AUTOSAR XML (schema 4-0-3)
standard types defined: Boolean, UInt16, UInt32, UInt8
package /AUTOSAR_Platform/DataConstrs
  range DC_Boolean: raw 0..1
  range DC_UInt16: raw 0..65535
  range DC_UInt8: raw 0..255
package /PATAC/MSM/ComponentTypes
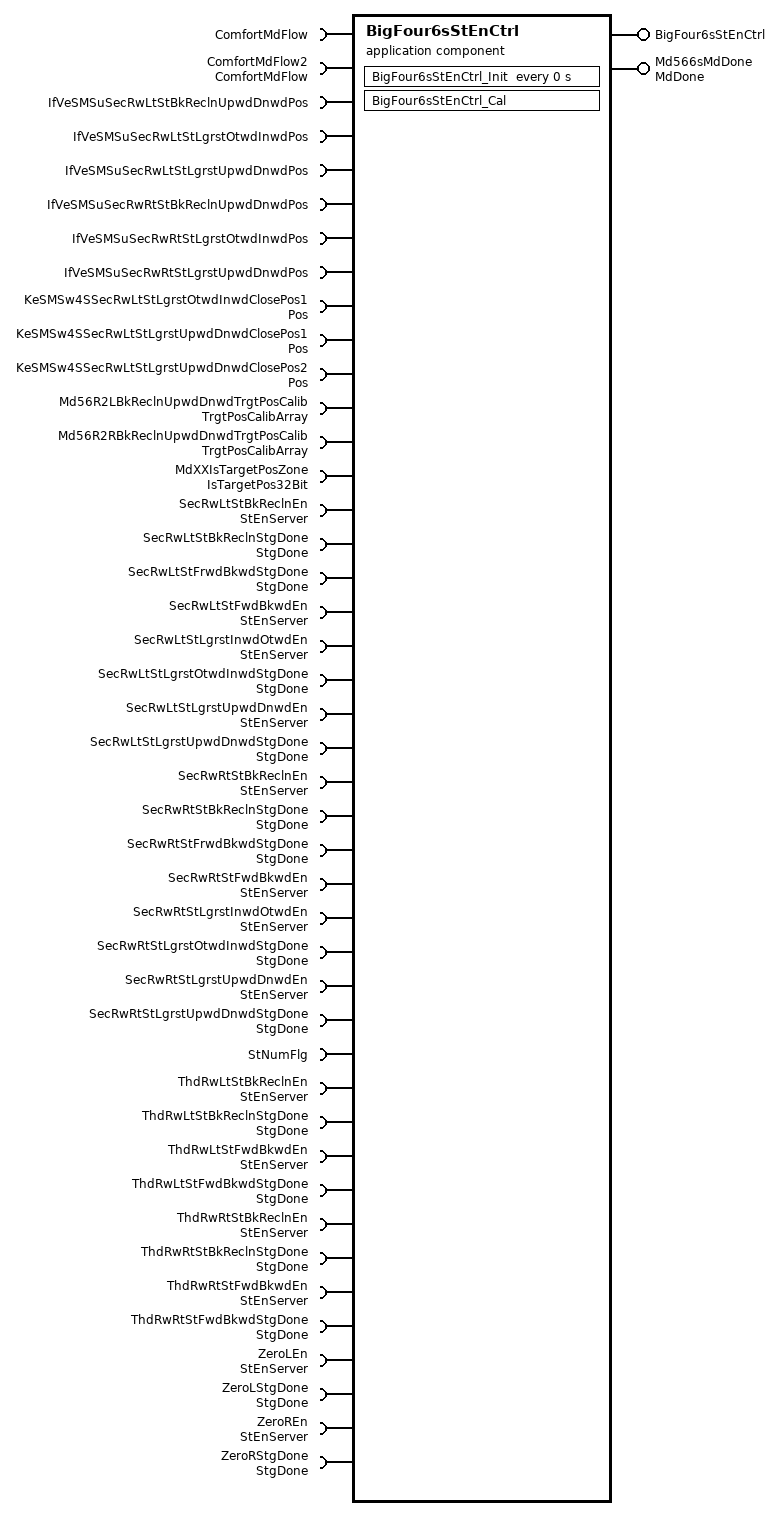
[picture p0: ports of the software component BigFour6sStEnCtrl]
  application sw component type BigFour6sStEnCtrl
    provide port BigFour6sStEnCtrl: server-com-spec{operation=BigFour6sStEnCtrl/Cal, queue-length=1}, provided-interface=BigFour6sStEnCtrl
    provide port Md566sMdDone: nonqueued-sender-com-spec{data-element=MdDone/Val, init-value=0}, provided-interface=MdDone
    43 x require port:
      ComfortMdFlow: client-com-spec=ComfortMdFlow/Cal, required-interface=ComfortMdFlow
      ComfortMdFlow2: client-com-spec=ComfortMdFlow/Cal, required-interface=ComfortMdFlow
      IfVeSMSuSecRwLtStBkReclnUpwdDnwdPos: nonqueued-receiver-com-spec{data-element=IfVeSMSuSecRwLtStBkReclnUpwdDnwdPos/Val, filter=data-filter-type=ALWAYS, init-value=0}, required-interface=IfVeSMSuSecRwLtStBkReclnUpwdDnwdPos
      IfVeSMSuSecRwLtStLgrstOtwdInwdPos: nonqueued-receiver-com-spec{data-element=IfVeSMSuSecRwLtStLgrstOtwdInwdPos/Val, filter=data-filter-type=ALWAYS, init-value=0}, required-interface=IfVeSMSuSecRwLtStLgrstOtwdInwdPos
      IfVeSMSuSecRwLtStLgrstUpwdDnwdPos: nonqueued-receiver-com-spec{data-element=IfVeSMSuSecRwLtStLgrstUpwdDnwdPos/Val, filter=data-filter-type=ALWAYS, init-value=0}, required-interface=IfVeSMSuSecRwLtStLgrstUpwdDnwdPos
      IfVeSMSuSecRwRtStBkReclnUpwdDnwdPos: nonqueued-receiver-com-spec{data-element=IfVeSMSuSecRwRtStBkReclnUpwdDnwdPos/Val, filter=data-filter-type=ALWAYS, init-value=0}, required-interface=IfVeSMSuSecRwRtStBkReclnUpwdDnwdPos
      IfVeSMSuSecRwRtStLgrstOtwdInwdPos: nonqueued-receiver-com-spec{data-element=IfVeSMSuSecRwRtStLgrstOtwdInwdPos/Val, filter=data-filter-type=ALWAYS, init-value=0}, required-interface=IfVeSMSuSecRwRtStLgrstOtwdInwdPos
      IfVeSMSuSecRwRtStLgrstUpwdDnwdPos: nonqueued-receiver-com-spec{data-element=IfVeSMSuSecRwRtStLgrstUpwdDnwdPos/Val, filter=data-filter-type=ALWAYS, init-value=0}, required-interface=IfVeSMSuSecRwRtStLgrstUpwdDnwdPos
      KeSMSw4SSecRwLtStLgrstOtwdInwdClosePos1: parameter-require-com-spec{init-value=0, parameter=Val}, required-interface=Pos
      KeSMSw4SSecRwLtStLgrstUpwdDnwdClosePos1: parameter-require-com-spec{init-value=0, parameter=Val}, required-interface=Pos
      KeSMSw4SSecRwLtStLgrstUpwdDnwdClosePos2: parameter-require-com-spec{init-value=0, parameter=Val}, required-interface=Pos
      Md56R2LBkReclnUpwdDnwdTrgtPosCalib: nonqueued-receiver-com-spec{data-element=TrgtPosArray, filter=data-filter-type=ALWAYS, init-value=[4095, 4095, 4095]}, required-interface=TrgtPosCalibArray
      Md56R2RBkReclnUpwdDnwdTrgtPosCalib: nonqueued-receiver-com-spec{data-element=TrgtPosArray, filter=data-filter-type=ALWAYS, init-value=[4095, 4095, 4095]}, required-interface=TrgtPosCalibArray
      MdXXIsTargetPosZone: nonqueued-receiver-com-spec{data-element=IsTargetPos32Bit/Val, filter=data-filter-type=ALWAYS, init-value=0}, required-interface=IsTargetPos32Bit
      SecRwLtStBkReclnEn: required-com-specs=[Clear, Get, Set], required-interface=StEnServer
      SecRwLtStBkReclnStgDone: nonqueued-receiver-com-spec{data-element=StgDone/Val, filter=data-filter-type=ALWAYS, init-value=0}, required-interface=StgDone
      SecRwLtStFrwdBkwdStgDone: nonqueued-receiver-com-spec{data-element=StgDone/Val, filter=data-filter-type=ALWAYS, init-value=0}, required-interface=StgDone
      SecRwLtStFwdBkwdEn: required-com-specs=[Clear, Get, Set], required-interface=StEnServer
      SecRwLtStLgrstInwdOtwdEn: required-com-specs=[Clear, Get, Set], required-interface=StEnServer
      SecRwLtStLgrstOtwdInwdStgDone: nonqueued-receiver-com-spec{data-element=StgDone/Val, filter=data-filter-type=ALWAYS, init-value=0}, required-interface=StgDone
      SecRwLtStLgrstUpwdDnwdEn: required-com-specs=[Clear, Get, Set], required-interface=StEnServer
      SecRwLtStLgrstUpwdDnwdStgDone: nonqueued-receiver-com-spec{data-element=StgDone/Val, filter=data-filter-type=ALWAYS, init-value=0}, required-interface=StgDone
      SecRwRtStBkReclnEn: required-com-specs=[Clear, Get, Set], required-interface=StEnServer
      SecRwRtStBkReclnStgDone: nonqueued-receiver-com-spec{data-element=StgDone/Val, filter=data-filter-type=ALWAYS, init-value=0}, required-interface=StgDone
      SecRwRtStFrwdBkwdStgDone: nonqueued-receiver-com-spec{data-element=StgDone/Val, filter=data-filter-type=ALWAYS, init-value=0}, required-interface=StgDone
      SecRwRtStFwdBkwdEn: required-com-specs=[Clear, Get, Set], required-interface=StEnServer
      SecRwRtStLgrstInwdOtwdEn: required-com-specs=[Clear, Get, Set], required-interface=StEnServer
      SecRwRtStLgrstOtwdInwdStgDone: nonqueued-receiver-com-spec{data-element=StgDone/Val, filter=data-filter-type=ALWAYS, init-value=0}, required-interface=StgDone
      SecRwRtStLgrstUpwdDnwdEn: required-com-specs=[Clear, Get, Set], required-interface=StEnServer
      SecRwRtStLgrstUpwdDnwdStgDone: nonqueued-receiver-com-spec{data-element=StgDone/Val, filter=data-filter-type=ALWAYS, init-value=0}, required-interface=StgDone
      StNumFlg: required-interface=StNumFlg
        required-com-specs:
          data-element=Is4s, filter=data-filter-type=ALWAYS, init-value=0
          data-element=Is6s, filter=data-filter-type=ALWAYS, init-value=0
          data-element=Is6s7s, filter=data-filter-type=ALWAYS, init-value=0
          data-element=Is7s, filter=data-filter-type=ALWAYS, init-value=0
      ThdRwLtStBkReclnEn: required-com-specs=[Clear, Get, Set], required-interface=StEnServer
      ThdRwLtStBkReclnStgDone: nonqueued-receiver-com-spec{data-element=StgDone/Val, filter=data-filter-type=ALWAYS, init-value=0}, required-interface=StgDone
      ThdRwLtStFwdBkwdEn: required-com-specs=[Clear, Get, Set], required-interface=StEnServer
      ThdRwLtStFwdBkwdStgDone: nonqueued-receiver-com-spec{data-element=StgDone/Val, filter=data-filter-type=ALWAYS, init-value=0}, required-interface=StgDone
      ThdRwRtStBkReclnEn: required-com-specs=[Clear, Get, Set], required-interface=StEnServer
      ThdRwRtStBkReclnStgDone: nonqueued-receiver-com-spec{data-element=StgDone/Val, filter=data-filter-type=ALWAYS, init-value=0}, required-interface=StgDone
      ThdRwRtStFwdBkwdEn: required-com-specs=[Clear, Get, Set], required-interface=StEnServer
      ThdRwRtStFwdBkwdStgDone: nonqueued-receiver-com-spec{data-element=StgDone/Val, filter=data-filter-type=ALWAYS, init-value=0}, required-interface=StgDone
      ZeroLEn: required-com-specs=[Clear, Get, Set], required-interface=StEnServer
      ZeroLStgDone: nonqueued-receiver-com-spec{data-element=StgDone/Val, filter=data-filter-type=ALWAYS, init-value=0}, required-interface=StgDone
      ZeroREn: required-com-specs=[Clear, Get, Set], required-interface=StEnServer
      ZeroRStgDone: nonqueued-receiver-com-spec{data-element=StgDone/Val, filter=data-filter-type=ALWAYS, init-value=0}, required-interface=StgDone
    behavior BigFour6sStEnCtrl_InternalBehavior
      operation invoked event OIT_BigFour6sStEnCtrl_Cal_BigFour6sStEnCtrl_Cal: start-on-event=BigFour6sStEnCtrl_Cal, operation=BigFour6sStEnCtrl.Cal
      timing event BigFour6sStEnCtrl_InitEvent: start-on-event=BigFour6sStEnCtrl_Init, period=0
      runnable BigFour6sStEnCtrl_Cal
        data-receive-point-by-arguments:
          27 x access:
            REC_IfVeSMSuSecRwLtStBkReclnUpwdDnwdPos_Val: accessed-variable=IfVeSMSuSecRwLtStBkReclnUpwdDnwdPos.Val
            REC_IfVeSMSuSecRwLtStLgrstOtwdInwdPos_Val: accessed-variable=IfVeSMSuSecRwLtStLgrstOtwdInwdPos.Val
            REC_IfVeSMSuSecRwLtStLgrstUpwdDnwdPos_Val: accessed-variable=IfVeSMSuSecRwLtStLgrstUpwdDnwdPos.Val
            REC_IfVeSMSuSecRwRtStBkReclnUpwdDnwdPos_Val: accessed-variable=IfVeSMSuSecRwRtStBkReclnUpwdDnwdPos.Val
            REC_IfVeSMSuSecRwRtStLgrstOtwdInwdPos_Val: accessed-variable=IfVeSMSuSecRwRtStLgrstOtwdInwdPos.Val
            REC_IfVeSMSuSecRwRtStLgrstUpwdDnwdPos_Val: accessed-variable=IfVeSMSuSecRwRtStLgrstUpwdDnwdPos.Val
            REC_Md56R2LBkReclnUpwdDnwdTrgtPosCalib_TrgtPosArray: accessed-variable=Md56R2LBkReclnUpwdDnwdTrgtPosCalib.TrgtPosArray
            REC_Md56R2RBkReclnUpwdDnwdTrgtPosCalib_TrgtPosArray: accessed-variable=Md56R2RBkReclnUpwdDnwdTrgtPosCalib.TrgtPosArray
            REC_MdXXIsTargetPosZone_Val: accessed-variable=MdXXIsTargetPosZone.Val
            REC_SecRwLtStBkReclnStgDone_Val: accessed-variable=SecRwLtStBkReclnStgDone.Val
            REC_SecRwLtStFrwdBkwdStgDone_Val: accessed-variable=SecRwLtStFrwdBkwdStgDone.Val
            REC_SecRwLtStLgrstOtwdInwdStgDone_Val: accessed-variable=SecRwLtStLgrstOtwdInwdStgDone.Val
            REC_SecRwLtStLgrstUpwdDnwdStgDone_Val: accessed-variable=SecRwLtStLgrstUpwdDnwdStgDone.Val
            REC_SecRwRtStBkReclnStgDone_Val: accessed-variable=SecRwRtStBkReclnStgDone.Val
            REC_SecRwRtStFrwdBkwdStgDone_Val: accessed-variable=SecRwRtStFrwdBkwdStgDone.Val
            REC_SecRwRtStLgrstOtwdInwdStgDone_Val: accessed-variable=SecRwRtStLgrstOtwdInwdStgDone.Val
            REC_SecRwRtStLgrstUpwdDnwdStgDone_Val: accessed-variable=SecRwRtStLgrstUpwdDnwdStgDone.Val
            REC_StNumFlg_Is4s: accessed-variable=StNumFlg.Is4s
            REC_StNumFlg_Is6s: accessed-variable=StNumFlg.Is6s
            REC_StNumFlg_Is6s7s: accessed-variable=StNumFlg.Is6s7s
            REC_StNumFlg_Is7s: accessed-variable=StNumFlg.Is7s
            REC_ThdRwLtStBkReclnStgDone_Val: accessed-variable=ThdRwLtStBkReclnStgDone.Val
            REC_ThdRwLtStFwdBkwdStgDone_Val: accessed-variable=ThdRwLtStFwdBkwdStgDone.Val
            REC_ThdRwRtStBkReclnStgDone_Val: accessed-variable=ThdRwRtStBkReclnStgDone.Val
            REC_ThdRwRtStFwdBkwdStgDone_Val: accessed-variable=ThdRwRtStFwdBkwdStgDone.Val
            REC_ZeroLStgDone_Val: accessed-variable=ZeroLStgDone.Val
            REC_ZeroRStgDone_Val: accessed-variable=ZeroRStgDone.Val
        data-send-points:
          access SEND_Md566sMdDone_Val: accessed-variable=Md566sMdDone.Val
        parameter access PA_KeSMSw4SSecRwLtStLgrstOtwdInwdClosePos1_Val: accessed-parameter=KeSMSw4SSecRwLtStLgrstOtwdInwdClosePos1.Val
        parameter access PA_KeSMSw4SSecRwLtStLgrstUpwdDnwdClosePos1_Val: accessed-parameter=KeSMSw4SSecRwLtStLgrstUpwdDnwdClosePos1.Val
        parameter access PA_KeSMSw4SSecRwLtStLgrstUpwdDnwdClosePos2_Val: accessed-parameter=KeSMSw4SSecRwLtStLgrstUpwdDnwdClosePos2.Val
        30 x sync call, all with timeout=0:
          SC_ComfortMdFlow_Cal: operation=ComfortMdFlow.Cal
          SC_ComfortMdFlow2_Cal: operation=ComfortMdFlow2.Cal
          SC_SecRwLtStBkReclnEn_Clear: operation=SecRwLtStBkReclnEn.Clear
          SC_SecRwLtStBkReclnEn_Set: operation=SecRwLtStBkReclnEn.Set
          SC_SecRwLtStFwdBkwdEn_Clear: operation=SecRwLtStFwdBkwdEn.Clear
          SC_SecRwLtStFwdBkwdEn_Set: operation=SecRwLtStFwdBkwdEn.Set
          SC_SecRwLtStLgrstInwdOtwdEn_Clear: operation=SecRwLtStLgrstInwdOtwdEn.Clear
          SC_SecRwLtStLgrstInwdOtwdEn_Set: operation=SecRwLtStLgrstInwdOtwdEn.Set
          SC_SecRwLtStLgrstUpwdDnwdEn_Clear: operation=SecRwLtStLgrstUpwdDnwdEn.Clear
          SC_SecRwLtStLgrstUpwdDnwdEn_Set: operation=SecRwLtStLgrstUpwdDnwdEn.Set
          SC_SecRwRtStBkReclnEn_Clear: operation=SecRwRtStBkReclnEn.Clear
          SC_SecRwRtStBkReclnEn_Set: operation=SecRwRtStBkReclnEn.Set
          SC_SecRwRtStFwdBkwdEn_Clear: operation=SecRwRtStFwdBkwdEn.Clear
          SC_SecRwRtStFwdBkwdEn_Set: operation=SecRwRtStFwdBkwdEn.Set
          SC_SecRwRtStLgrstInwdOtwdEn_Clear: operation=SecRwRtStLgrstInwdOtwdEn.Clear
          SC_SecRwRtStLgrstInwdOtwdEn_Set: operation=SecRwRtStLgrstInwdOtwdEn.Set
          SC_SecRwRtStLgrstUpwdDnwdEn_Clear: operation=SecRwRtStLgrstUpwdDnwdEn.Clear
          SC_SecRwRtStLgrstUpwdDnwdEn_Set: operation=SecRwRtStLgrstUpwdDnwdEn.Set
          SC_ThdRwLtStBkReclnEn_Clear: operation=ThdRwLtStBkReclnEn.Clear
          SC_ThdRwLtStBkReclnEn_Set: operation=ThdRwLtStBkReclnEn.Set
          SC_ThdRwLtStFwdBkwdEn_Clear: operation=ThdRwLtStFwdBkwdEn.Clear
          SC_ThdRwLtStFwdBkwdEn_Set: operation=ThdRwLtStFwdBkwdEn.Set
          SC_ThdRwRtStBkReclnEn_Clear: operation=ThdRwRtStBkReclnEn.Clear
          SC_ThdRwRtStBkReclnEn_Set: operation=ThdRwRtStBkReclnEn.Set
          SC_ThdRwRtStFwdBkwdEn_Clear: operation=ThdRwRtStFwdBkwdEn.Clear
          SC_ThdRwRtStFwdBkwdEn_Set: operation=ThdRwRtStFwdBkwdEn.Set
          SC_ZeroLEn_Clear: operation=ZeroLEn.Clear
          SC_ZeroLEn_Set: operation=ZeroLEn.Set
          SC_ZeroREn_Clear: operation=ZeroREn.Clear
          SC_ZeroREn_Set: operation=ZeroREn.Set
      runnable BigFour6sStEnCtrl_Init
        parameter access PA_KeSMSw4SSecRwLtStLgrstOtwdInwdClosePos1_Val: accessed-parameter=KeSMSw4SSecRwLtStLgrstOtwdInwdClosePos1.Val
        parameter access PA_KeSMSw4SSecRwLtStLgrstUpwdDnwdClosePos1_Val: accessed-parameter=KeSMSw4SSecRwLtStLgrstUpwdDnwdClosePos1.Val
        parameter access PA_KeSMSw4SSecRwLtStLgrstUpwdDnwdClosePos2_Val: accessed-parameter=KeSMSw4SSecRwLtStLgrstUpwdDnwdClosePos2.Val
  swc implementation BigFour6sStEnCtrl_Implementation: behavior=BigFour6sStEnCtrl_InternalBehavior
    code-descriptors:
      code Default: artifact-descriptors=autosar-engineering-object={short-label=Default, category=SWSRC}
package /PATAC/MSM/ModeAdjust/CalPortInterface
  parameter interface Pos
    parameter data prototype Val: sw-calibration-access=READ-WRITE, type=UInt16
package /PATAC/MSM/ModeAdjust/DataType
  impl type TrgtPosCalibArray: category=ARRAY, sw-calibration-access=READ-ONLY, type-emitter=RTE  # 0:pos 1:max 2:min
    element Element: array-size=3, array-size-semantics=FIXED-SIZE, implementation-data-type=UInt16, invalid-value=0
package /PATAC/MSM/ModeAdjust/PortInterface
  client server interface BigFour6sStEnCtrl
    operation Cal
  client server interface ComfortMdFlow
    operation Cal
      14 x arg, all with server-argument-impl-policy=USE-ARGUMENT-TYPE:
        LgrstUpwdDnwdPos: type=UInt16, direction=IN
        LgrstUpwdDnwdClosePos1: type=UInt16, direction=IN
        LgrstUpwdStgDone: type=Implementation/Boolean, direction=IN
        ZeroStgDone: type=Implementation/Boolean, direction=IN
        LgrstInwdStgDone: type=Implementation/Boolean, direction=IN
        Failflg: type=Implementation/Boolean, direction=OUT
        LgrstInwdOtwdEn: type=Implementation/Boolean, direction=OUT
        LgrstUpwdDnwdEn: type=Implementation/Boolean, direction=OUT
        ZeroEn: type=Implementation/Boolean, direction=OUT
        BkReclnStgDone: type=DataTypes/Boolean, direction=IN
        BkReclnEn: type=DataTypes/Boolean, direction=OUT
        LgrstUpwdDnwdClosePos2: type=UInt16, direction=IN
        LgrstInwdOtwdClosePos1: type=UInt16, direction=IN
        LgrstInwdOtwdPos: type=UInt16, direction=IN
  client server interface StEnServer
    operation Clear
      arg data: type=UInt8, direction=IN, server-argument-impl-policy=USE-ARGUMENT-TYPE
    operation Get
      arg data: type=UInt32, direction=OUT, server-argument-impl-policy=USE-ARGUMENT-TYPE
    operation Set
      arg data: type=UInt8, direction=IN, server-argument-impl-policy=USE-ARGUMENT-TYPE
  5 x sender receiver interface:
    IsTargetPos32Bit: invalidation-policy{data-element=IsTargetPos32Bit/Val, handle-invalid=DONT-INVALIDATE}
      data Val: type=UInt32
    MdDone: invalidation-policy{data-element=MdDone/Val, handle-invalid=DONT-INVALIDATE}
      data Val: type=UInt8
    StgDone: invalidation-policy{data-element=StgDone/Val, handle-invalid=DONT-INVALIDATE}
      data Val: type=Implementation/Boolean
    StNumFlg
      4 x data, all with type=Implementation/Boolean:
        Is4s
        Is6s
        Is6s7s
        Is7s
      invalidation-policys:
        data-element=Is4s, handle-invalid=DONT-INVALIDATE
        data-element=Is6s, handle-invalid=DONT-INVALIDATE
        data-element=Is6s7s, handle-invalid=DONT-INVALIDATE
        data-element=Is7s, handle-invalid=DONT-INVALIDATE
    TrgtPosCalibArray: invalidation-policy{data-element=TrgtPosArray, handle-invalid=DONT-INVALIDATE}
      data TrgtPosArray: type=TrgtPosCalibArray  # 0:Pos 1:Max 2:Min
package /PATAC/MSM/PortInterfaces
  6 x sender receiver interface:
    IfVeSMSuSecRwLtStBkReclnUpwdDnwdPos: invalidation-policy{data-element=IfVeSMSuSecRwLtStBkReclnUpwdDnwdPos/Val, handle-invalid=DONT-INVALIDATE}
      data Val: type=UInt16
    IfVeSMSuSecRwLtStLgrstOtwdInwdPos: invalidation-policy{data-element=IfVeSMSuSecRwLtStLgrstOtwdInwdPos/Val, handle-invalid=DONT-INVALIDATE}
      data Val: type=UInt16
    IfVeSMSuSecRwLtStLgrstUpwdDnwdPos: invalidation-policy{data-element=IfVeSMSuSecRwLtStLgrstUpwdDnwdPos/Val, handle-invalid=DONT-INVALIDATE}
      data Val: type=UInt16
    IfVeSMSuSecRwRtStBkReclnUpwdDnwdPos: invalidation-policy{data-element=IfVeSMSuSecRwRtStBkReclnUpwdDnwdPos/Val, handle-invalid=DONT-INVALIDATE}
      data Val: type=UInt16
    IfVeSMSuSecRwRtStLgrstOtwdInwdPos: invalidation-policy{data-element=IfVeSMSuSecRwRtStLgrstOtwdInwdPos/Val, handle-invalid=DONT-INVALIDATE}
      data Val: type=UInt16
    IfVeSMSuSecRwRtStLgrstUpwdDnwdPos: invalidation-policy{data-element=IfVeSMSuSecRwRtStLgrstUpwdDnwdPos/Val, handle-invalid=DONT-INVALIDATE}
      data Val: type=UInt16
